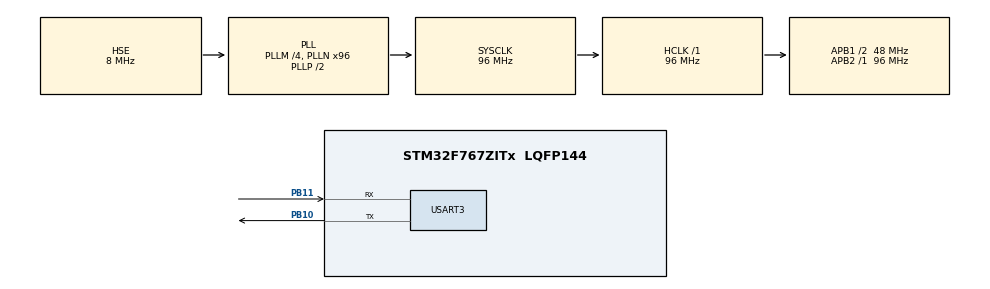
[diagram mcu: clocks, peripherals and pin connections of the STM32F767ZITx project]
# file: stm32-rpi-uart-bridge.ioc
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Mcu.Family=STM32F7
Mcu.Name=STM32F767ZITx
Mcu.Package=LQFP144
NVIC.PriorityGroup=NVIC_PRIORITYGROUP_4
NVIC.USART3_IRQn=true\:0\:0\:false\:false\:true\:true\:true\:true
PB10.Mode=Asynchronous
PB10.Signal=USART3_TX
PB11.Mode=Asynchronous
PB11.Signal=USART3_RX
PH0/OSC_IN.Mode=HSE-External-Oscillator
PH0/OSC_IN.Signal=RCC_OSC_IN
PH1/OSC_OUT.Mode=HSE-External-Oscillator
PH1/OSC_OUT.Signal=RCC_OSC_OUT
ProjectManager.HeapSize=0x200
ProjectManager.StackSize=0x400
ProjectManager.TargetToolchain=STM32CubeIDE
RCC.48MHZClocksFreq_Value=24000000
RCC.AHBFreq_Value=96000000
RCC.APB1CLKDivider=RCC_HCLK_DIV2
RCC.APB1Freq_Value=48000000
RCC.APB1TimFreq_Value=96000000
RCC.APB2Freq_Value=96000000
RCC.APB2TimFreq_Value=96000000
RCC.CortexFreq_Value=96000000
RCC.HCLKFreq_Value=96000000
RCC.HSE_VALUE=8000000
RCC.HSI_VALUE=16000000
RCC.PLLM=4
RCC.PLLMUL=RCC_PLL_MUL9
RCC.PLLN=96
RCC.PLLQ=4
RCC.PLLSourceVirtual=RCC_PLLSOURCE_HSE
RCC.PRESCALERUSB=RCC_USBCLKSOURCE_PLL_DIV1_5
RCC.SYSCLKFreq_VALUE=96000000
RCC.SYSCLKSource=RCC_SYSCLKSOURCE_PLLCLK
RCC.SYSCLKSourceVirtual=RCC_SYSCLKSOURCE_PLLCLK
RCC.USBFreq_Value=48000000
RCC.VCOOutputFreq_Value=192000000
USART3.VirtualMode-Asynchronous=VM_ASYNC
board=NUCLEO-F767ZI

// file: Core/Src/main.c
/* USER CODE BEGIN Header */
/**
  ******************************************************************************
  * @file           : main.c
  * @brief          : Main program body
  ******************************************************************************
  * @attention
  *
  * Copyright (c) 2026 STMicroelectronics.
  * All rights reserved.
  *
  * This software is licensed under terms that can be found in the LICENSE file
  * in the root directory of this software component.
  * If no LICENSE file comes with this software, it is provided AS-IS.
  *
  ******************************************************************************
  */
/* USER CODE END Header */
#include "main.h"
#include "string.h"
#include "stdio.h"

UART_HandleTypeDef huart3;

void SystemClock_Config(void);
static void MX_GPIO_Init(void);
static void MX_USART3_UART_Init(void);

/* USER CODE BEGIN 0 */
#define RX_BUFFER_SIZE 64
uint8_t rx_byte;
char rx_buffer[RX_BUFFER_SIZE];
uint8_t rx_index = 0;
uint8_t receiving = 0;
/* USER CODE END 0 */

int main(void)
{

  /* MCU Configuration--------------------------------------------------------*/

  /* Reset of all peripherals, Initializes the Flash interface and the Systick. */
  HAL_Init();

  /* Configure the system clock */
  SystemClock_Config();

  /* Initialize all configured peripherals */
  MX_GPIO_Init();
  MX_USART3_UART_Init();

  // --- START UART INTERRUPT RECEIVE ---
  HAL_UART_Receive_IT(&huart3, &rx_byte, 1);

  /* Infinite loop */
  while (1)
  {

  }
}

void SystemClock_Config(void)
{
  RCC_OscInitTypeDef RCC_OscInitStruct = {0};
  RCC_ClkInitTypeDef RCC_ClkInitStruct = {0};

  /** Configure the main internal regulator output voltage
  */
  __HAL_RCC_PWR_CLK_ENABLE();
  __HAL_PWR_VOLTAGESCALING_CONFIG(PWR_REGULATOR_VOLTAGE_SCALE3);

  /** Initializes the RCC Oscillators according to the specified parameters
  * in the RCC_OscInitTypeDef structure.
  */
  RCC_OscInitStruct.OscillatorType = RCC_OSCILLATORTYPE_HSE;
  RCC_OscInitStruct.HSEState = RCC_HSE_ON;
  RCC_OscInitStruct.PLL.PLLState = RCC_PLL_ON;
  RCC_OscInitStruct.PLL.PLLSource = RCC_PLLSOURCE_HSE;
  RCC_OscInitStruct.PLL.PLLM = 4;
  RCC_OscInitStruct.PLL.PLLN = 96;
  RCC_OscInitStruct.PLL.PLLP = RCC_PLLP_DIV2;
  RCC_OscInitStruct.PLL.PLLQ = 4;
  RCC_OscInitStruct.PLL.PLLR = 2;
  if (HAL_RCC_OscConfig(&RCC_OscInitStruct) != HAL_OK)
  {
    Error_Handler();
  }

  /** Activate the Over-Drive mode
  */
  if (HAL_PWREx_EnableOverDrive() != HAL_OK)
  {
    Error_Handler();
  }

  /** Initializes the CPU, AHB and APB buses clocks
  */
  RCC_ClkInitStruct.ClockType = RCC_CLOCKTYPE_HCLK|RCC_CLOCKTYPE_SYSCLK
                              |RCC_CLOCKTYPE_PCLK1|RCC_CLOCKTYPE_PCLK2;
  RCC_ClkInitStruct.SYSCLKSource = RCC_SYSCLKSOURCE_PLLCLK;
  RCC_ClkInitStruct.AHBCLKDivider = RCC_SYSCLK_DIV1;
  RCC_ClkInitStruct.APB1CLKDivider = RCC_HCLK_DIV2;
  RCC_ClkInitStruct.APB2CLKDivider = RCC_HCLK_DIV1;

  if (HAL_RCC_ClockConfig(&RCC_ClkInitStruct, FLASH_LATENCY_3) != HAL_OK)
  {
    Error_Handler();
  }
}

static void MX_USART3_UART_Init(void)
{

  huart3.Instance = USART3;
  huart3.Init.BaudRate = 115200;
  huart3.Init.WordLength = UART_WORDLENGTH_8B;
  huart3.Init.StopBits = UART_STOPBITS_1;
  huart3.Init.Parity = UART_PARITY_NONE;
  huart3.Init.Mode = UART_MODE_TX_RX;
  huart3.Init.HwFlowCtl = UART_HWCONTROL_NONE;
  huart3.Init.OverSampling = UART_OVERSAMPLING_16;
  huart3.Init.OneBitSampling = UART_ONE_BIT_SAMPLE_DISABLE;
  huart3.AdvancedInit.AdvFeatureInit = UART_ADVFEATURE_NO_INIT;
  if (HAL_UART_Init(&huart3) != HAL_OK)
  {
    Error_Handler();
  }

}

static void MX_GPIO_Init(void)
{
/* USER CODE BEGIN MX_GPIO_Init_1 */
   GPIO_InitTypeDef GPIO_InitStruct = {0};
/* USER CODE END MX_GPIO_Init_1 */

  /* GPIO Ports Clock Enable */
  __HAL_RCC_GPIOH_CLK_ENABLE();
  __HAL_RCC_GPIOB_CLK_ENABLE();
  __HAL_RCC_USART3_CLK_ENABLE();

/* USER CODE BEGIN MX_GPIO_Init_2 */
  /* USART3 TX PB10 */
  GPIO_InitStruct.Pin = GPIO_PIN_10;
  GPIO_InitStruct.Mode = GPIO_MODE_AF_PP;
  GPIO_InitStruct.Pull = GPIO_PULLUP;
  GPIO_InitStruct.Speed = GPIO_SPEED_FREQ_VERY_HIGH;
  GPIO_InitStruct.Alternate = GPIO_AF7_USART3;
  HAL_GPIO_Init(GPIOB, &GPIO_InitStruct);

  /* USART3 RX PB11 */
  GPIO_InitStruct.Pin = GPIO_PIN_11;
  GPIO_InitStruct.Mode = GPIO_MODE_AF_PP;
  GPIO_InitStruct.Pull = GPIO_PULLUP;
  GPIO_InitStruct.Alternate = GPIO_AF7_USART3;
  HAL_GPIO_Init(GPIOB, &GPIO_InitStruct);
/* USER CODE END MX_GPIO_Init_2 */
}

/* USER CODE BEGIN 4 */
// UART receive complete callback
void HAL_UART_RxCpltCallback(UART_HandleTypeDef *huart)
{
    if (huart->Instance == USART3)
    {
        if (rx_byte == 0x02)  // STX
        {
            receiving = 1;
            rx_index = 0;
        }
        else if (rx_byte == 0x03 && receiving)  // ETX
        {
            rx_buffer[rx_index] = '\0';
            receiving = 0;

            // ---- COMMAND PARSING ----
            if (strcmp(rx_buffer, "|PING|") == 0)
            {
                char reply[] = "\x02|PONG|\x03";
                HAL_UART_Transmit(&huart3, (uint8_t*)reply, strlen(reply), HAL_MAX_DELAY);
            }
            else if (strcmp(rx_buffer, "|STATUS|") == 0)
            {
                char reply[40];
                sprintf(reply, "\x02|STATUS|OK|\x03");
                HAL_UART_Transmit(&huart3, (uint8_t*)reply, strlen(reply), HAL_MAX_DELAY);
            }
        }
        else if (receiving && rx_index < RX_BUFFER_SIZE - 1)
        {
            rx_buffer[rx_index++] = rx_byte;
        }

        // Re-enable interrupt for next byte
        HAL_UART_Receive_IT(&huart3, &rx_byte, 1);
    }
}
/* USER CODE END 4 */

void Error_Handler(void)
{
  __disable_irq();
  while (1)
  {
  }
}
